# STM32F733xx register map
File version: 1.0
Registers are 32-bit, access not given, reset 0x0 unless marked. A register's access mark holds for its fields unless they carry their own. Offsets are from the block's base; [hi:lo] are bit positions; {n}, {i} and the like mark numbered series.

## ADC1
Base 0x40012000
Same registers: ADC3 0x40012200
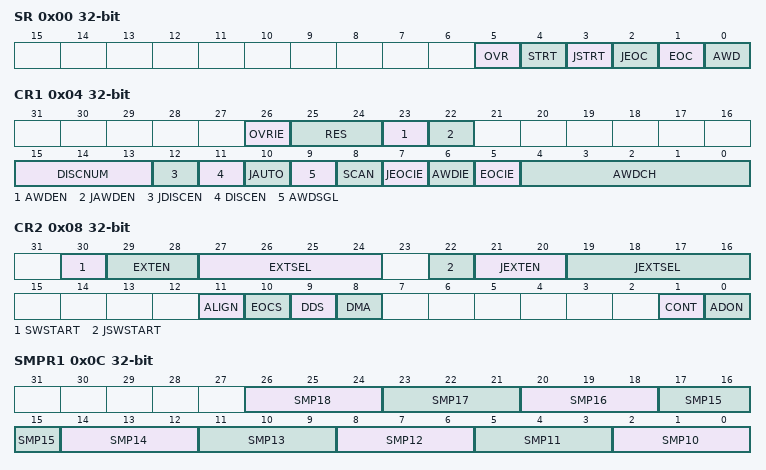
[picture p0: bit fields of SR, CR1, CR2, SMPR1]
0x00 SR
  [5] OVR, [4] STRT, [3] JSTRT, [2] JEOC, [1] EOC, [0] AWD
0x04 CR1
  [26] OVRIE, [25:24] RES, [23] AWDEN, [22] JAWDEN, [15:13] DISCNUM, [12] JDISCEN, [11] DISCEN, [10] JAUTO, [9] AWDSGL, [8] SCAN, [7] JEOCIE, [6] AWDIE, [5] EOCIE, [4:0] AWDCH
0x08 CR2
  [30] SWSTART, [29:28] EXTEN, [27:24] EXTSEL, [22] JSWSTART, [21:20] JEXTEN, [19:16] JEXTSEL, [11] ALIGN, [10] EOCS, [9] DDS, [8] DMA, [1] CONT, [0] ADON
0x0C SMPR1
  [3n-28:3n-30] SMP{n} (n=10..18)
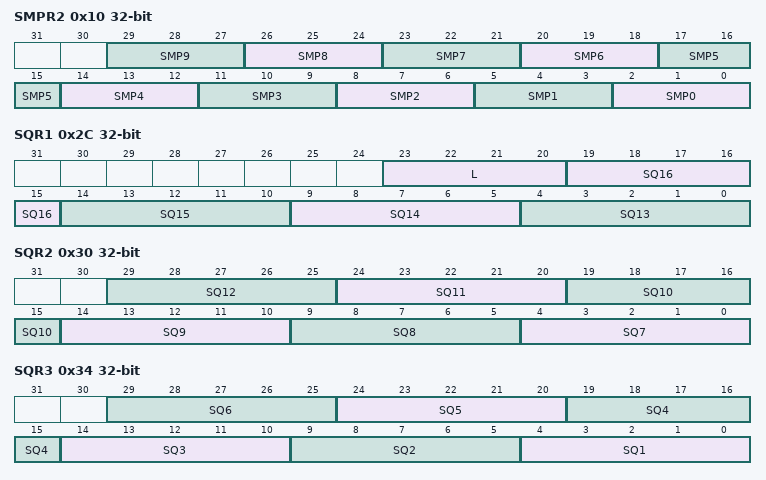
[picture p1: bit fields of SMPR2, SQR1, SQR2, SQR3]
0x10 SMPR2
  [3n+2:3n] SMP{n} (n=0..9)
{0x10+4i} JOFR{i} (i=1..4)
  [11:0] JOFFSET{i}
0x24 HTR
  [11:0] HT
0x28 LTR
  [11:0] LT
0x2C SQR1
  [23:20] L, [5n-61:5n-65] SQ{n} (n=13..16)
0x30 SQR2
  [5n-31:5n-35] SQ{n} (n=7..12)
0x34 SQR3
  [5n-1:5n-5] SQ{n} (n=1..6)
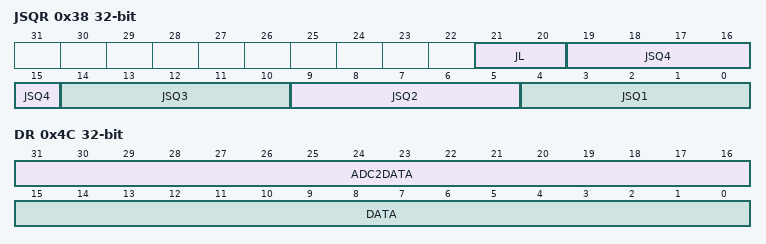
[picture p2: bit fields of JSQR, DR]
0x38 JSQR
  [21:20] JL, [5n-1:5n-5] JSQ{n} (n=1..4)
{0x38+4i} JDR{i} (i=1..4)
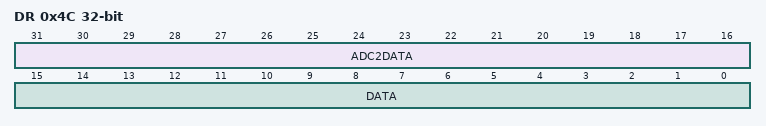
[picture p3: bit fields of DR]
0x4C DR
  [31:16] ADC2DATA, [15:0] DATA

## ADC2
Base 0x40012100
Registers as ADC1; these are added or differ:
0x4C DR
  [31:16] ADC2DATA, [15:0] DATA

## ADC
Base 0x40012300
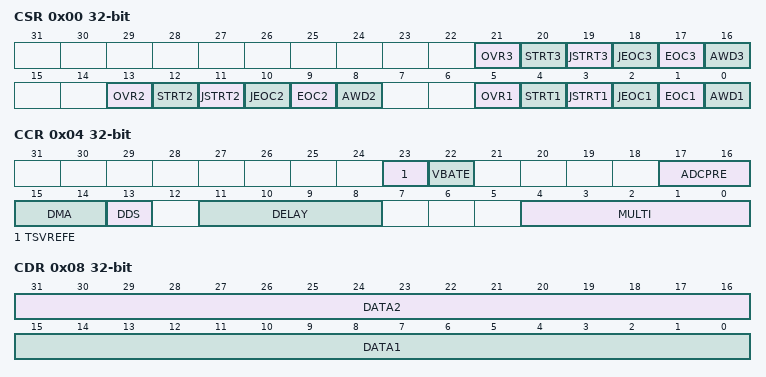
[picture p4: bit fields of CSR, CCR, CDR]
0x00 CSR
  [21] OVR3, [20] STRT3, [19] JSTRT3, [18] JEOC3, [17] EOC3, [16] AWD3, [13] OVR2, [12] STRT2, [11] JSTRT2, [10] JEOC2, [9] EOC2, [8] AWD2, [5] OVR1, [4] STRT1, [3] JSTRT1, [2] JEOC1, [1] EOC1, [0] AWD1
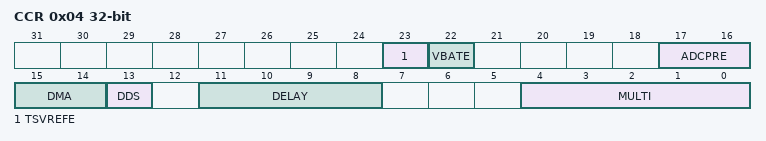
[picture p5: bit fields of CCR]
0x04 CCR
  [23] TSVREFE, [22] VBATE, [17:16] ADCPRE, [15:14] DMA, [13] DDS, [11:8] DELAY, [4:0] MULTI
0x08 CDR
  [31:16] DATA2, [15:0] DATA1

## ADC123_COMMON
Base 0x40012300
Registers as ADC; these are added or differ:
0x04 CCR
  [23] TSVREFE, [22] VBATE, [17:16] ADCPRE, [15:14] DMA, [13] DDS, [11:8] DELAY, [4:0] MULTI

## SYSCFG
Base 0x40013800
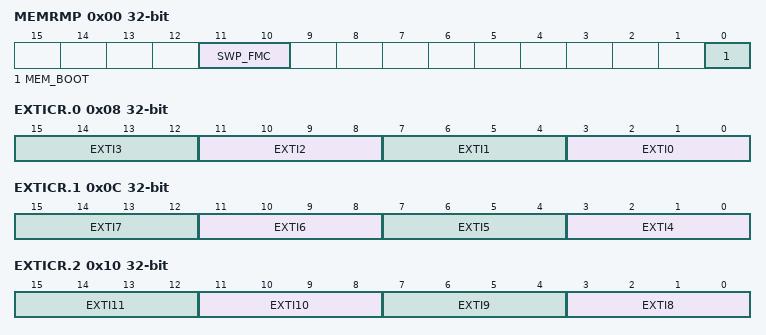
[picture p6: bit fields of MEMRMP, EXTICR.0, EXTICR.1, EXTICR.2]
0x00 MEMRMP
  [11:10] SWP_FMC, [0] MEM_BOOT
0x04 PMC
  [18] ADC3DC2, [17] ADC2DC2, [18:16] ADCxDC2, [n-2] I2C_PB{n}_FMP (n=6..9), [2] I2C3_FMP, [1] I2C2_FMP, [0] I2C1_FMP
0x08 EXTICR.0
  [4n+3:4n] EXTI{n} (n=0..3)
0x0C EXTICR.1
  [4n-13:4n-16] EXTI{n} (n=4..7)
0x10 EXTICR.2
  [4n-29:4n-32] EXTI{n} (n=8..11)
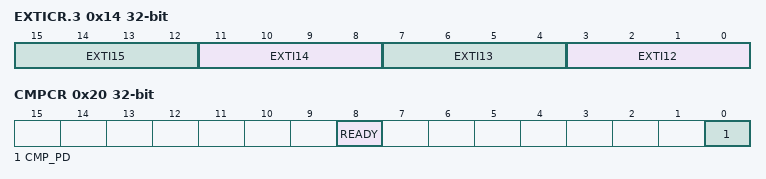
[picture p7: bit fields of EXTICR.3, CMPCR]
0x14 EXTICR.3
  [4n-45:4n-48] EXTI{n} (n=12..15)
0x20 CMPCR
  [8] READY, [0] CMP_PD

## EXTI
Base 0x40013C00
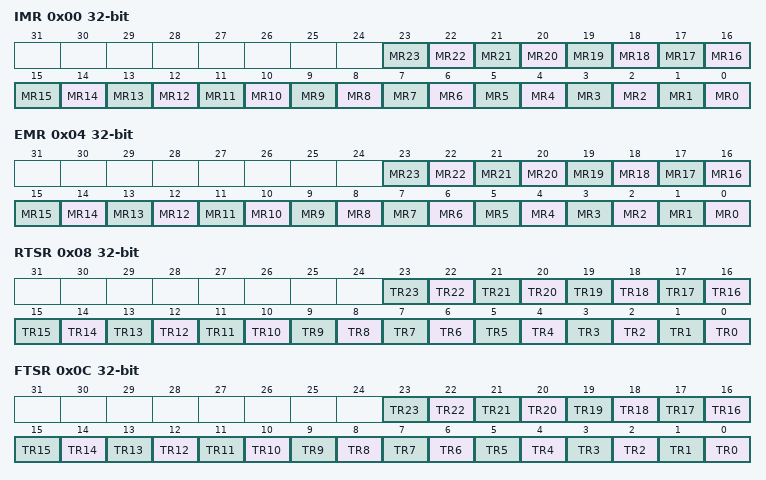
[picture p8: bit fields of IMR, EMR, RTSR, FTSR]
0x00 IMR
  [n] MR{n} (n=0..23)
0x04 EMR
  [n] MR{n} (n=0..23)
0x08 RTSR
  [n] TR{n} (n=0..23)
0x0C FTSR
  [n] TR{n} (n=0..23)
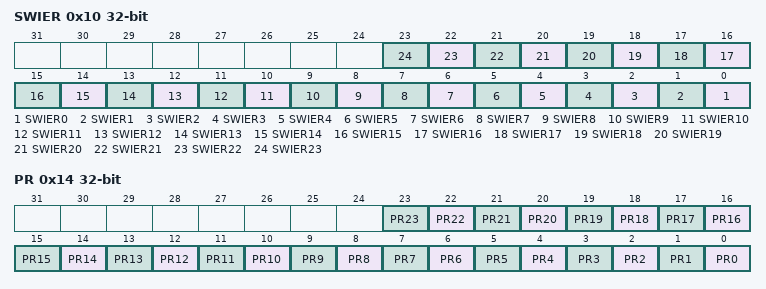
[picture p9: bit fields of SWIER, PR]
0x10 SWIER
  [n] SWIER{n} (n=0..23)
0x14 PR
  [n] PR{n} (n=0..23)

## SAI1
Base 0x40015800
Same registers: SAI2 0x40015C00
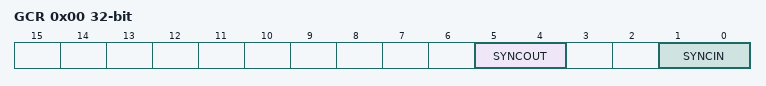
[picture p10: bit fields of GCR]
0x00 GCR
  [5:4] SYNCOUT, [1:0] SYNCIN
0x04 CR1A
0x08 CR2A
0x10 FRCRA
0x1C SLOTRA
0x24 CR1B
0x28 CR2B
0x2C IMRA
0x30 FRCRB
0x3C SLOTRB
0x40 SRA
0x4C IMRB
0x58 CLRFRA
0x60 SRB
0x74 DRA
0x78 CLRFRB
0x94 DRB

## USB_HS_PHYC
Base 0x40017C00
0x00 USB_HS_PHYC_PLL
0x0C USB_HS_PHYC_TUNE
0x18 USB_HS_PHYC_LDO

## GPIOA
Base 0x40020000
Same registers: GPIOB 0x40020400, GPIOC 0x40020800, GPIOD 0x40020C00, GPIOE 0x40021000, GPIOF 0x40021400, GPIOG 0x40021800, GPIOH 0x40021C00, GPIOI 0x40022000
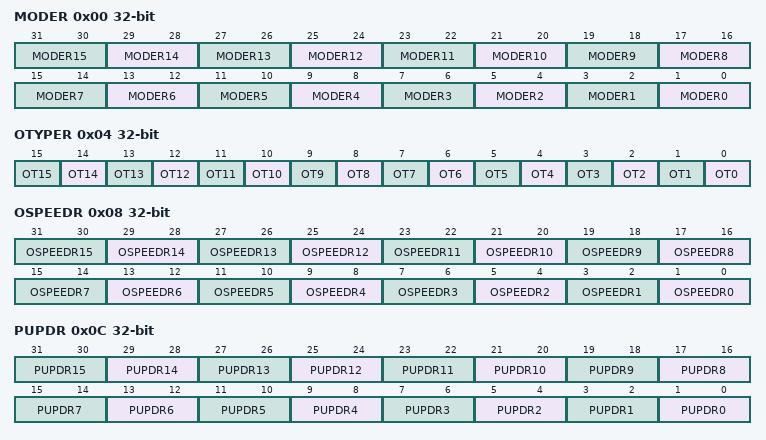
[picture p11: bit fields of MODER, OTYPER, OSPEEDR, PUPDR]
0x00 MODER
  [2n+1:2n] MODER{n} (n=0..15)
0x04 OTYPER
  [n] OT{n} (n=0..15)
0x08 OSPEEDR
  [2n+1:2n] OSPEEDR{n} (n=0..15)
0x0C PUPDR
  [2n+1:2n] PUPDR{n} (n=0..15)
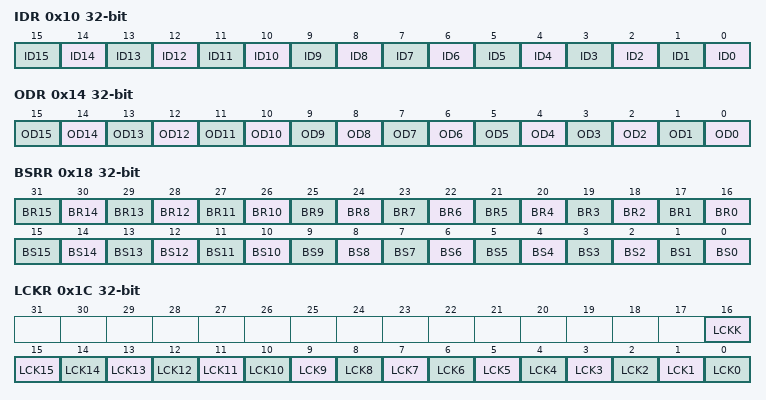
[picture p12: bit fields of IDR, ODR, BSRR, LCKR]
0x10 IDR
  [n] ID{n} (n=0..15)
0x14 ODR
  [n] OD{n} (n=0..15)
0x18 BSRR
  [n+16] BR{n} (n=0..15), [n] BS{n} (n=0..15)
0x1C LCKR
  [16] LCKK, [n] LCK{n} (n=0..15)
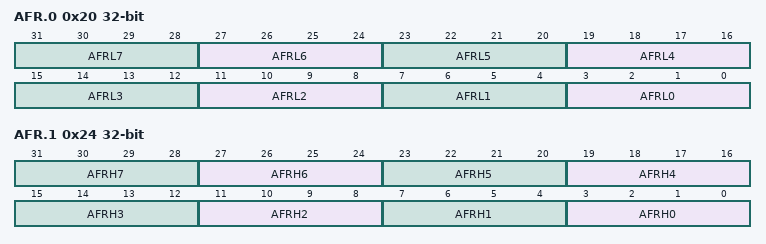
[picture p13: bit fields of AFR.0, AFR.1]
0x20 AFR.0
  [4n+3:4n] AFRL{n} (n=0..7)
0x24 AFR.1
  [4n+3:4n] AFRH{n} (n=0..7)

## CRC
Base 0x40023000
0x00 DR
0x04 IDR 8-bit
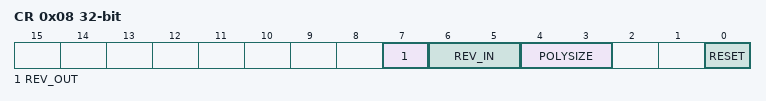
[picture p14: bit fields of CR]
0x08 CR
  [7] REV_OUT, [6:5] REV_IN, [4:3] POLYSIZE, [0] RESET
0x10 INIT
0x14 POL

## FLASH
Base 0x40023C00
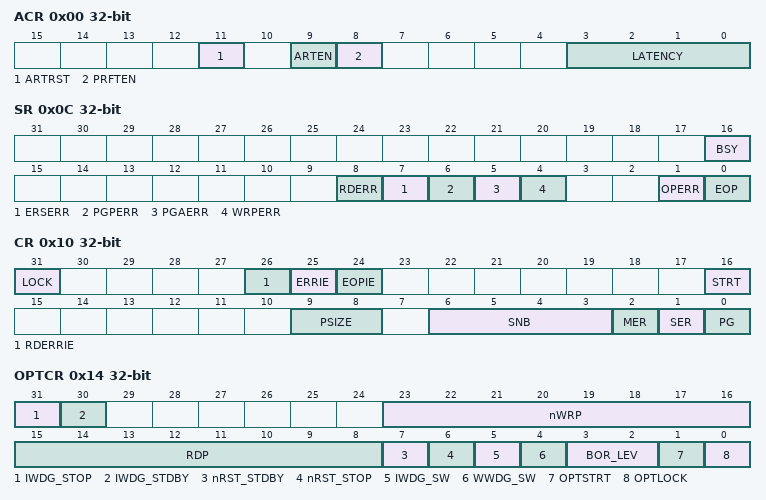
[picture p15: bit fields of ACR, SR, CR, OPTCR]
0x00 ACR
  [11] ARTRST, [9] ARTEN, [8] PRFTEN, [3:0] LATENCY
0x04 KEYR
0x08 OPTKEYR
0x0C SR
  [16] BSY, [8] RDERR, [7] ERSERR, [6] PGPERR, [5] PGAERR, [4] WRPERR, [1] OPERR, [0] EOP
0x10 CR
  [31] LOCK, [26] RDERRIE, [25] ERRIE, [24] EOPIE, [16] STRT, [9:8] PSIZE, [6:3] SNB, [2] MER, [1] SER, [0] PG
0x14 OPTCR
  [31] IWDG_STOP, [30] IWDG_STDBY, [23:16] nWRP, [15:8] RDP, [7] nRST_STDBY, [6] nRST_STOP, [5] IWDG_SW, [4] WWDG_SW, [3:2] BOR_LEV, [1] OPTSTRT, [0] OPTLOCK
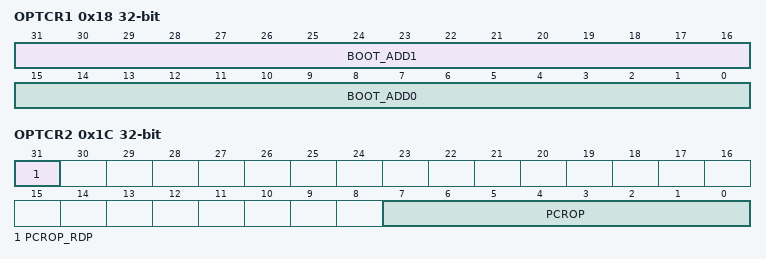
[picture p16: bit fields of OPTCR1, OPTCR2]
0x18 OPTCR1
  [31:16] BOOT_ADD1, [15:0] BOOT_ADD0
0x1C OPTCR2
  [31] PCROP_RDP, [7:0] PCROP
